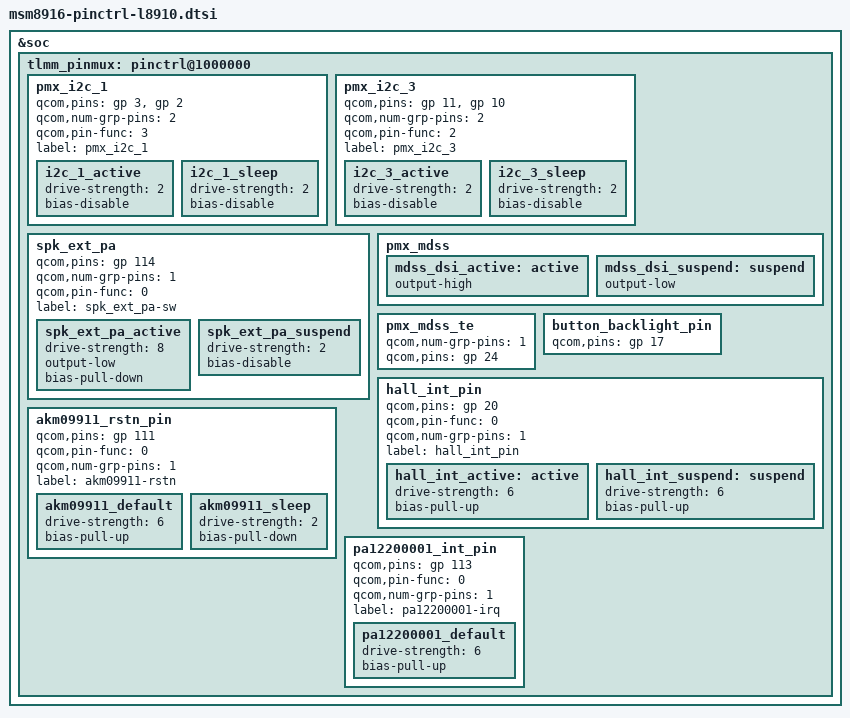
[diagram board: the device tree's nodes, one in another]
/* Copyright (c) 2013-2014, The Linux Foundation. All rights reserved.
 *
 * This program is free software; you can redistribute it and/or modify
 * it under the terms of the GNU General Public License version 2 and
 * only version 2 as published by the Free Software Foundation.
 *
 * This program is distributed in the hope that it will be useful,
 * but WITHOUT ANY WARRANTY; without even the implied warranty of
 * MERCHANTABILITY or FITNESS FOR A PARTICULAR PURPOSE.  See the
 * GNU General Public License for more details.
 */

#include "../msm8916-pinctrl.dtsi"

&soc {
	tlmm_pinmux: pinctrl@1000000 {

		pmx_i2c_1 {
			/* CLK, DATA */
			qcom,pins = <&gp 3>, <&gp 2>;
			qcom,num-grp-pins = <2>;
			qcom,pin-func = <3>;
			label = "pmx_i2c_1";
 
			i2c_1_active: i2c_1_active {
				drive-strength = <2>; /* 2 MA */
				bias-disable;	     /* No PULL */
			};
 
			i2c_1_sleep: i2c_1_sleep {
				drive-strength = <2>; /* 2 MA */
				bias-disable;	     /* No PULL */
			};
		};
 
		pmx_i2c_3 {
			/* CLK, DATA */
			qcom,pins = <&gp 11>, <&gp 10>;
			qcom,num-grp-pins = <2>;
			qcom,pin-func = <2>;
			label = "pmx_i2c_3";
		
			i2c_3_active: i2c_3_active {
				drive-strength = <2>; /* 2 MA */
				bias-disable;	     /* No PULL */
			};
		
			i2c_3_sleep: i2c_3_sleep {
				drive-strength = <2>; /* 2 MA */
				bias-disable;	     /* No PULL */
			};
		};
		
		spk_ext_pa {
			qcom,pins = <&gp 114>;
			qcom,num-grp-pins = <1>;
			qcom,pin-func = <0>;
			label = "spk_ext_pa-sw";
			spk_ext_pa_active: spk_ext_pa_active {
				drive-strength = <8>;
				output-low;
				bias-pull-down;
			};
			spk_ext_pa_suspend: spk_ext_pa_suspend {
				drive-strength = <2>;
				bias-disable;
			};
		};

		pmx_mdss: pmx_mdss {
			mdss_dsi_active: active {
				output-high;
			};
			mdss_dsi_suspend: suspend {
				output-low;
			};
		};

		pmx_mdss_te: pmx_mdss_te {
			qcom,num-grp-pins = <1>;
			qcom,pins = <&gp 24>;
		};

		button_backlight_pin {
			qcom,pins = <&gp 17>;
		};

		hall_int_pin{
			qcom,pins = <&gp 20>;
			qcom,pin-func = <0>;
			qcom,num-grp-pins = <1>;
			label = "hall_int_pin";
			hall_int_active: active {
				drive-strength = <6>;
				bias-pull-up;
			};
			hall_int_suspend: suspend {
				drive-strength = <6>;
				bias-pull-up;
			};
		};
 
		akm09911_rstn_pin {
			qcom,pins = <&gp 111>;
			qcom,pin-func = <0>;
			qcom,num-grp-pins = <1>;
			label = "akm09911-rstn";
			akm09911_default: akm09911_default {
				  drive-strength = <6>;
				  bias-pull-up;
			};
			akm09911_sleep: akm09911_sleep {
				drive-strength = <2>;
				bias-pull-down;
			};
		};
 
		pa12200001_int_pin {
			qcom,pins = <&gp 113>;
			qcom,pin-func = <0>;
			qcom,num-grp-pins = <1>;
			label = "pa12200001-irq";
			pa12200001_default: pa12200001_default {
				drive-strength = <6>;
				bias-pull-up;
			};
		};


	};
};
